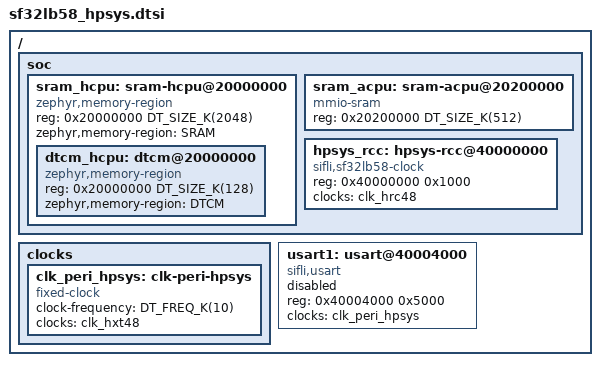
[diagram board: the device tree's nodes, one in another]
/*
 * Copyright (c) 2025 Qingdao IotPi Ltd.
 *
 * SPDX-License-Identifier: Apache-2.0
 */

#include <arm/armv8-m.dtsi>
#include <sifli/sf32lb58.dtsi>
#include <mem.h>

/ {
    soc {
		#address-cells = <1>;
		#size-cells = <1>;

        /* accessible from both hcpu and acpu */
        sram_hcpu: sram-hcpu@20000000 {
            compatible = "zephyr,memory-region", "mmio-sram";
            reg = <0x20000000 DT_SIZE_K(2048)>;
            zephyr,memory-region = "SRAM";

		    #address-cells = <1>;
		    #size-cells = <1>;

            dtcm_hcpu: dtcm@20000000 {
                compatible = "zephyr,memory-region", "mmio-sram";
                reg = <0x20000000 DT_SIZE_K(128)>;
                zephyr,memory-region = "DTCM";
            };
        };

        sram_acpu: sram-acpu@20200000 {
            compatible = "mmio-sram";
            reg = <0x20200000 DT_SIZE_K(512)>;
        };

        hpsys_rcc: hpsys-rcc@40000000 {
            compatible = "sifli,sf32lb58-clock";
            #clock-cells = <0>;
            reg = <0x40000000 0x1000>;
            /* #clock-config-cells = <2>; */
            /* clock-configs = <& 0x14 0x00>; */
            clocks = <&clk_hrc48>;
        };
    };

    clocks {
        clk_peri_hpsys: clk-peri-hpsys {
            compatible = "fixed-clock";
            #clock-cells = <0>; /* clock, selection */
            clock-frequency = <DT_FREQ_K(10)>;
            clocks = <&clk_hxt48>;
        };
    };

    usart1: usart@40004000 {
        compatible = "sifli,usart";
        reg = <0x40004000 0x5000>;
        status = "disabled";
        clocks = <&clk_peri_hpsys>;
    };
};
